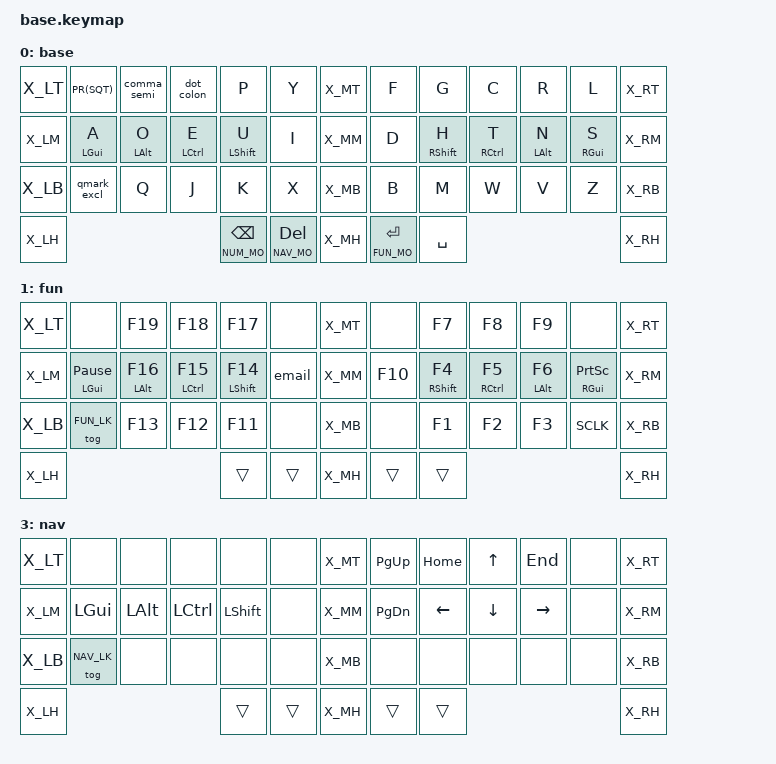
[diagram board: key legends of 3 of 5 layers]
// Defines the base keymap from which to derive keyboard specific maps.
// Copyright Paul W. Berg

// This program is free software: you can redistribute it and/or modify
// it under the terms of the GNU Affero General Public License as published by
// the Free Software Foundation, either version 3 of the License, or
// (at your option) any later version.
//
// This program is distributed in the hope that it will be useful,
// but WITHOUT ANY WARRANTY; without even the implied warranty of
// MERCHANTABILITY or FITNESS FOR A PARTICULAR PURPOSE.  See the
// GNU Affero General Public License for more details.
//
// You should have received a copy of the GNU Affero General Public License// along with this program.  If not, see <http://www.gnu.org/licenses/>.

#include <behaviors.dtsi>
#include <dt-bindings/zmk/keys.h>
#include "extra_keys.h"
#include "timing.h"

// If we are wireless, set a key row up for connecting
#ifdef CONFIG_WIRELESS
    #include <dt-bindings/zmk/bt.h>
    #define BT_SEL_KEY_ROW &bt BT_SEL 0 &bt BT_SEL 1 &bt BT_SEL 2 &bt BT_SEL 3 &bt BT_CLR
#else
    #define BT_SEL_KEY_ROW &trans &trans &trans &trans
#endif

// Use require-prior-idle-ms for combos
#define COMBO_HOOK require-prior-idle-ms = <REQUIRE_PRIOR_IDLE_TERM>;
#include "zmk_helper.h"

// If we want to persist a layer beyond some sticky layer term we run into an issue.
// This is useful in cases such as one handed ten key entry or arrow navigation.
// When any ZMK momentary layer switch ends, such as releasing the key in the case of
// momentary layer switch, or the expiration of the sticky term for a sticky layer, ZMK
// naturally deactivates the layer. This means that anything we do to persist that layer
// while the layer is temporarally active will also be dismissed, foiling our plans.
// We can avoid this by instead switching to a higher level transparent layer and activating
// the layer we would like indirectly as a conditional layer. Then, when the temporary
// transparent layer is dismissed, the target layer will not be (explicitly) dismissed.
// However, the target layer, being conditional, must have a true condition in order to be
// active at all. To enable the target layer we create yet another transparent layer that
// also conditionally activates the target layer that will not be explicitly dismissed
// when the temporary layer is. To permanently activate the target layer we can toggle this
// second transparent layer on which will conditionally activate the target layer and
// persist once the momentary layer is dismissed. This way we can simply create a toggle key
// on the target layer and the target layer will persist beyond the dismissal of the
// momentary layer. Here we define such transparent layers with a _MO and _LK suffix.
// These layers are completely transparent and only serve as conditional switches for
// the target layer.
#define DEF 0
#define FUN 1
#define NUM 2
#define NAV 3
#define SYS 4
#define FUN_MO 5
#define FUN_LK 6
#define NUM_MO 7
#define NUM_LK 8
#define NAV_MO 9
#define NAV_LK 10
#define SYS_MO 11
#define SYS_LK 12

#define FUNS FUN FUN_MO FUN_LK
#define NUMS NUM NUM_MO NUM_LK
#define NAVS NAV NAV_MO NAV_LK
#define SYSS SYS SYS_MO SYS_LK

// Key pairs, such as () and [] are defined later to create the opening char on tap, both on hold and insert cursor between.
// The macro thar creates them creates a device tree binding to &pair_KEYNAME which takes
// an ignored key and the KENAME itself. This macro allows us to refer to this hold tap behavior as PR(KEYNAME).
// For example, open parenthesis is refered to as PR(LPAR).
#define PR(OPEN) &pair_ ## OPEN 0 OPEN

// Combos need layers defined first
#include "combos.dtsi"

//////////////////////////////
// Global behavior defalts
&caps_word {
  /delete-property/ ignore-modifiers;
};

// mod-tap confg
&mt {
  flavor = "tap-preferred";
  tapping-term-ms = <TAPPING_TERM>;
  quick-tap-ms = <QUICK_TAP_TERM>;
  hold-trigger-key-positions = <0>;
};

// layer-tap config
&lt {
  flavor = "balanced";
  tapping-term-ms = <TAPPING_TERM>;
  quick-tap-ms = <QUICK_TAP_TERM>;
};

// sticky-key config
&sk {
  release-after-ms = <STICKY_TERM>;

  // no double capitalization when rolling keys
  quick-release;
};

// sticky-layer config
&sl {
  // allow chording sticky mods & layers
  ignore-modifiers;
};

// Paired chars. Open on tap, pair on hold with cursor inside.
// This is an ambiguous hold on HMR so we can't do it there because we can't tell if hold is a mod or pair.
#define MAKE_PAIR(OPEN, CLOSE) \
  ZMK_BEHAVIOR(pair_macro_ ## OPEN, macro, \
    bindings = <&macro_tap &kp OPEN &kp CLOSE> \
      , <&macro_release &kp LSHFT &kp RSHFT> \
      , <&macro_tap &kp LEFT>; \
  ) \
  ZMK_BEHAVIOR(pair_ ## OPEN, hold_tap, \
    flavor = "balanced"; \
    tapping-term-ms = <TAPPING_TERM>; \
    quick-tap-ms = <QUICK_TAP_TERM>; \
    bindings = <&pair_macro_ ## OPEN>, <&kp>; \
  )

MAKE_PAIR(LBKT, RIGHT_BRACKET)
MAKE_PAIR(LBRC, RIGHT_BRACE)
MAKE_PAIR(SQT, SINGLE_QUOTE)
MAKE_PAIR(GRAVE, GRAVE)
MAKE_PAIR(PRCNT, PERCENT)

// Hold for Q, tap for Qu
// Not currently active. I don't think I like this. Maybe better as 2 separate combos rather than a linger.
ZMK_BEHAVIOR(m_qu, macro,
  wait-ms = <0>;
  tap-ms = <0>;
  bindings = <&macro_tap &kp Q>
    , <&macro_release &kp LSHFT &kp RSHFT>
    , <&macro_tap &kp U>;
)

ZMK_BEHAVIOR(qu_q, hold_tap,
  flavor = "tap-preferred";
  tapping-term-ms = <TAPPING_TERM>;
  quick-tap-ms = <QUICK_TAP_TERM>;
  bindings = <&kp>, <&m_qu>;
)

// Macro to create behaviors for home row mods by reducing cross hand false negatives
#define MAKE_HRM(NAME, HOLD, TAP, TRIGGER_POS) \
  ZMK_BEHAVIOR(NAME, hold_tap, \
    flavor = "balanced"; \
    tapping-term-ms = <TAPPING_TERM>; \
    quick-tap-ms = <QUICK_TAP_TERM>; \
    require-prior-idle-ms = <REQUIRE_PRIOR_IDLE_TERM>; \
    bindings = <HOLD>, <TAP>; \
    hold-trigger-key-positions = <TRIGGER_POS>; \
    hold-trigger-on-release; \
  )

// Left and right hand home row mods
MAKE_HRM(hml, &kp, &kp, KEYS_R THUMBS)
MAKE_HRM(hmr, &kp, &kp, KEYS_L THUMBS)

// Used for HRM combos
MAKE_HRM(hml_repeat, &kp, &key_repeat, KEYS_R THUMBS)
MAKE_HRM(hmr_lpar_lt, &kp, &lpar_lt, KEYS_L THUMBS)
MAKE_HRM(hmr_rpar_gt, &kp, &rpar_gt, KEYS_L THUMBS)

// Basic non-shifted / shifted key variants.
ZMK_SIMPLE_MORPH(lpar_lt, SFT, &kp LEFT_PARENTHESIS, &kp LESS_THAN)
ZMK_SIMPLE_MORPH(rpar_gt, SFT, &kp RIGHT_PARENTHESIS, &kp GREATER_THAN)
ZMK_SIMPLE_MORPH(comma_semi, SFT, &kp COMMA, &kp SEMICOLON)
ZMK_SIMPLE_MORPH(dot_colon, SFT, &kp DOT, &kp COLON)
ZMK_SIMPLE_MORPH(fslh_star, SFT, &kp SLASH, &kp STAR)
ZMK_SIMPLE_MORPH(qmark_excl, SFT, &kp QUESTION, &kp EXCLAMATION)
ZMK_SIMPLE_MORPH(minus_plus, SFT, &kp MINUS, &kp PLUS)
ZMK_SIMPLE_MORPH(under_crt, SFT, &kp UNDERSCORE, &kp CARET)
ZMK_SIMPLE_MORPH(tld_prcnt, SFT, &kp TILDE, PR(PRCNT))
ZMK_SIMPLE_MORPH(hash_dllr, SFT, &kp HASH, &kp DOLLAR)
ZMK_SIMPLE_MORPH(eq_bslh, SFT, &kp EQUAL, &kp BACKSLASH)
ZMK_SIMPLE_MORPH(caps_ins, SFT, &caps_word, &kp INSERT)

// Turn off some keyboard shortcuts to get me into the habit of using my kb ones
//ZMK_SIMPLE_MORPH(c_off, CTL, &kp C, &none)
//ZMK_SIMPLE_MORPH(v_off, CTL, &kp V, &none)
//ZMK_SIMPLE_MORPH(x_off, CTL, &kp X, &none)
//ZMK_SIMPLE_MORPH(a_off, CTL, &kp A, &none)

// My email address for binding to key
ZMK_BEHAVIOR(email, macro,
  bindings = <&kp P &kp A &kp U &kp L &kp AT &kp P &kp A &kp U &kp L &kp W &kp B &kp E &kp R &kp G &kp DOT &kp C &kp O &kp M>;
)

// Set up conditional layer triggers
ZMK_CONDITIONAL_LAYER(numMo, NUM_MO, NUM)
ZMK_CONDITIONAL_LAYER(numLk, NUM_LK, NUM)
ZMK_CONDITIONAL_LAYER(navMo, NAV_MO, NAV)
ZMK_CONDITIONAL_LAYER(navLk, NAV_LK, NAV)
ZMK_CONDITIONAL_LAYER(funMo, FUN_MO, FUN)
ZMK_CONDITIONAL_LAYER(funLk, FUN_LK, FUN)
ZMK_CONDITIONAL_LAYER(sysMo, SYS_MO, SYS)
ZMK_CONDITIONAL_LAYER(sysLk, SYS_LK, SYS)
ZMK_CONDITIONAL_LAYER(sys, NAV FUN, SYS_MO)

// Copy an argument X times
#define ZMK_COPY_X2(x) x x
#define ZMK_COPY_X4(x) ZMK_COPY_X2(x) ZMK_COPY_X2(x)
#define ZMK_COPY_X8(x) ZMK_COPY_X4(x) ZMK_COPY_X4(x)
#define ZMK_COPY_X16(x) ZMK_COPY_X8(x) ZMK_COPY_X8(x)
#define ZMK_COPY_X32(x) ZMK_COPY_X16(x) ZMK_COPY_X16(x)

// Make key layout pretty
#define XXX &none
#define ___ &trans
#define LT_FUN_RET &lt FUN_MO RET
#define LT_NAV_DEL &lt NAV_MO DEL
#define LT_NUM_BSPC &lt NUM_MO BSPC

ZMK_LAYER(base,
//╭──────╮ ╭─────────────┬─────────────┬─────────────┬─────────────┬─────────────╮ ╭──────╮ ╭─────────────┬─────────────┬─────────────┬─────────────┬─────────────╮ ╭──────╮
    X_LT     PR(SQT)       &comma_semi   &dot_colon    &kp P         &kp Y           X_MT     &kp F         &kp G         &kp C         &kp R         &kp L           X_RT
//├──────┤ ├────────────┼─────────────┼─────────────┼─────────────┼──────────────┤ ├──────┤ ├─────────────┼─────────────┼─────────────┼─────────────┼─────────────┤ ├──────┤
    X_LM     &hml LGUI A   &hml LALT O   &hml LCTRL E  &hml LSHFT U  &kp I           X_MM     &kp D         &hmr RSHFT H  &hmr RCTRL T  &hmr LALT N   &hmr RGUI S     X_RM
//├──────┤ ├─────────────┼─────────────┼─────────────┼─────────────┼─────────────┤ ├──────┤ ├─────────────┼─────────────┼─────────────┼─────────────┼─────────────┤ ├──────┤
    X_LB     &qmark_excl   &kp Q         &kp J         &kp K         &kp X           X_MB     &kp B         &kp M         &kp W         &kp V        &kp Z           X_RB
//├──────┤ ╰─────────────┼─────────────┴─────────────┼─────────────┼─────────────┤ ├──────┤ ├─────────────┼─────────────┼─────────────┴───────────────────────────╯ ├──────┤
    X_LH                                               LT_NUM_BSPC   LT_NAV_DEL      X_MH     LT_FUN_RET    &kp SPACE                                                 X_RH
//╰──────╯                                           ╰─────────────┴─────────────╯ ╰──────╯ ╰─────────────┴─────────────╯                                           ╰──────╯
)

#define HRM_PAUSE &hml LGUI PAUSE_BREAK

ZMK_LAYER(fun,
//╭──────╮ ╭─────────────┬─────────────┬─────────────┬─────────────┬─────────────╮ ╭──────╮ ╭─────────────┬─────────────┬─────────────┬─────────────┬─────────────╮ ╭──────╮
    X_LT     XXX           &kp F19       &kp F18       &kp F17       XXX             X_MT     XXX           &kp F7        &kp F8        &kp F9        XXX             X_RT
//├──────┤ ├─────────────┼─────────────┼─────────────┼─────────────┼─────────────┤ ├──────┤ ├─────────────┼─────────────┼─────────────┼─────────────┼─────────────┤ ├──────┤
    X_LM     HRM_PAUSE     &hml LALT F16 &hml LCTRL F15 &hml LSHFT F14 &email        X_MM     &kp F10       &hmr RSHFT F4 &hmr RCTRL F5 &hmr LALT F6  &hmr RGUI PSCRN X_RM
//├──────┤ ├─────────────┼─────────────┼─────────────┼─────────────┼─────────────┤ ├──────┤ ├─────────────┼─────────────┼─────────────┼─────────────┼─────────────┤ ├──────┤
    X_LB     &tog FUN_LK   &kp F13       &kp F12        &kp F11      XXX             X_MB     XXX           &kp F1        &kp F2        &kp F3        &kp SCLK        X_RB
//├──────┤ ╰─────────────┼─────────────┴─────────────┼─────────────┼─────────────┤ ├──────┤ ├─────────────┼─────────────┼─────────────┴───────────────────────────╯ ├──────┤
    X_LH                                               ___           ___             X_MH     ___           ___                                                       X_RH
//╰──────╯                                           ╰─────────────┴─────────────╯ ╰──────╯ ╰─────────────┴─────────────╯                                           ╰──────╯
)

// Number layer
// 10-key like on right hand. X, Y, I and N are exposed for scientific calculator use.
#define HMR_NUMPAD &none &hmr RSHFT KP_N4 &hmr RCTRL KP_N5 &hmr LALT KP_N6 &kp RGUI
#define LT_FUN_0 &lt FUN_MO KP_N0

ZMK_LAYER(num,
//╭──────╮ ╭─────────────┬─────────────┬─────────────┬─────────────┬─────────────╮ ╭──────╮ ╭─────────────┬─────────────┬─────────────┬─────────────┬─────────────╮ ╭──────╮
    X_LT     XXX           XXX           XXX           XXX           &kp Q           X_MT     XXX           &kp KP_N7     &kp KP_N8     &kp KP_N9     XXX             X_RT
//├──────┤ ├─────────────┼─────────────┼─────────────┼─────────────┼─────────────┤ ├──────┤ ├─────────────┼─────────────┼─────────────┼─────────────┼─────────────┤ ├──────┤
    X_LM     &kp LGUI      &kp LALT      &kp LCTRL     &kp LSHFT     &kp L           X_MM                                 HMR_NUMPAD                                  X_RM
//├──────┤ ├─────────────┼─────────────┼─────────────┼─────────────┼─────────────┤ ├──────┤ ├─────────────┼─────────────┼─────────────┼─────────────┼─────────────┤ ├──────┤
    X_LB     &tog NUM_LK   XXX           XXX           XXX           XXX             X_MB     XXX           &kp KP_N1     &kp KP_N2     &kp KP_N3     XXX             X_RB
//├──────┤ ╰─────────────┼─────────────┴─────────────┼─────────────┼─────────────┤ ├──────┤ ├─────────────┼─────────────┼─────────────┴───────────────────────────╯ ├──────┤
    X_LH                                               ___           ___             X_MH     LT_FUN_0      &dot_colon                                                X_RH
//╰──────╯                                           ╰─────────────┴─────────────╯ ╰──────╯ ╰─────────────┴─────────────╯                                           ╰──────╯
)

ZMK_LAYER(nav,
//╭──────╮ ╭─────────────┬─────────────┬─────────────┬─────────────┬─────────────╮ ╭──────╮ ╭─────────────┬─────────────┬─────────────┬─────────────┬─────────────╮ ╭──────╮
    X_LT     XXX           XXX           XXX           XXX           XXX             X_MT     &kp PG_UP     &kp HOME      &kp UP        &kp END       XXX             X_RT
//├──────┤ ├─────────────┼─────────────┼─────────────┼─────────────┼─────────────┤ ├──────┤ ├─────────────┼─────────────┼─────────────┼─────────────┼─────────────┤ ├──────┤
    X_LM     &kp LGUI      &kp LALT      &kp LCTRL     &kp LSHFT     XXX             X_MM     &kp PG_DN     &kp LEFT      &kp DOWN      &kp RIGHT     XXX             X_RM
//├──────┤ ├─────────────┼─────────────┼─────────────┼─────────────┼─────────────┤ ├──────┤ ├─────────────┼─────────────┼─────────────┼─────────────┼─────────────┤ ├──────┤
    X_LB     &tog NAV_LK   XXX           XXX           XXX           XXX             X_MB     XXX           XXX           XXX           XXX           XXX             X_RB
//├──────┤ ╰─────────────┼─────────────┴─────────────┼─────────────┼─────────────┤ ├──────┤ ├─────────────┼─────────────┼─────────────┴───────────────────────────╯ ├──────┤
    X_LH                                               ___           ___             X_MH     ___           ___                                                       X_RH
//╰──────╯                                           ╰─────────────┴─────────────╯ ╰──────╯ ╰─────────────┴─────────────╯                                           ╰──────╯
)

ZMK_LAYER(sys,
//╭──────╮ ╭─────────────┬─────────────┬─────────────┬─────────────┬─────────────╮ ╭──────╮ ╭─────────────┬─────────────┬─────────────┬─────────────┬─────────────╮ ╭──────╮
    X_LT                                BT_SEL_KEY_ROW                               X_MT     XXX           XXX           XXX           XXX           XXX             X_RT
//├──────┤ ├─────────────┼─────────────┼─────────────┼─────────────┼─────────────┤ ├──────┤ ├─────────────┼─────────────┼─────────────┼─────────────┼─────────────┤ ├──────┤
    X_LM     XXX           XXX           XXX           XXX           &bootloader     X_MM     &bootloader   XXX           XXX           XXX           XXX             X_RM
//├──────┤ ├─────────────┼─────────────┼─────────────┼─────────────┼─────────────┤ ├──────┤ ├─────────────┼─────────────┼─────────────┼─────────────┼─────────────┤ ├──────┤
    X_LB     &tog SYS_LK   &sys_reset    XXX           XXX           XXX             X_MB     XXX           XXX           XXX           &sys_reset    XXX             X_RB
//├──────┤ ╰─────────────┼─────────────┴─────────────┼─────────────┼─────────────┤ ├──────┤ ├─────────────┼─────────────┼─────────────┴───────────────────────────╯ ├──────┤
    X_LH                                               ___           ___             X_MH     ___           ___                                                       X_RH
//╰──────╯                                           ╰─────────────┴─────────────╯ ╰──────╯ ╰─────────────┴─────────────╯                                           ╰──────╯
)

// Create a layer consisting of only transparent keys
#define TRANSPARENT_LAYER(name) ZMK_LAYER(name, ZMK_COPY_X32(&trans) &trans &trans)

TRANSPARENT_LAYER(fun_mo)
TRANSPARENT_LAYER(fun_lk)
TRANSPARENT_LAYER(num_mo)
TRANSPARENT_LAYER(num_lk)
TRANSPARENT_LAYER(nav_mo)
TRANSPARENT_LAYER(nav_lk)
TRANSPARENT_LAYER(sys_mo)
TRANSPARENT_LAYER(sys_lk)
